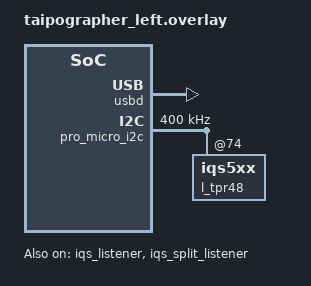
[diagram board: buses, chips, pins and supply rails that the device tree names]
#include "taipographer.dtsi"

&usbd {
  status = "okay";
};

&pro_micro_i2c {
  status = "okay";
  clock-frequency = <I2C_BITRATE_FAST>;

  // The local trackpad
  l_tpr48: iqs5xx@74 {
    #include "overlays/tpr48.overlay"
    status = "okay";
  };
};

// Listen to the local trackpad
&iqs_listener {
  status = "okay";
  device = <&l_tpr48>;
};

// Listen to the peripheral's trackpad
&iqs_split_listener {
  status = "okay";
};
